# MSPM0L134X register map
Vendor: Texas Instruments; File version: This preliminary header file does not have a version number - build date: 2023-02-21 16:43:37
CPU: CM0 r0p1, little endian, MPU, no FPU, 3 interrupt priority bits
Registers are 32-bit, read-write, reset 0x0 unless marked. A register's access mark holds for its fields unless they carry their own. Offsets are from the block's base; [hi:lo] are bit positions; {n}, {i} and the like mark numbered series.

## SYSCTL — mem_map
Base 0x400AF000
0x1020 IIDX ro — SYSCTL interrupt index
  [1:0] IIDX_STAT — The SYSCTL interrupt index (IIDX) register generates a value corresponding to the highest priority pending interrupt source. This value may be used as an address offset for fast, deterministic handling in the interrupt service routine. A read of the IIDX register will clear the corresponding interrupt status in the RIS and MIS registers.
    0=IIDX_STAT_NO_INTR (NO_INTR); 1=IIDX_STAT_LFOSCGOOD (LFOSCGOOD); 2=IIDX_STAT_ANACLKERR (ANACLKERR)
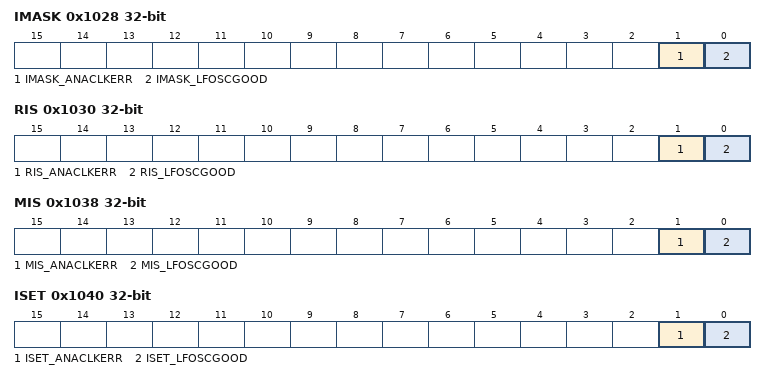
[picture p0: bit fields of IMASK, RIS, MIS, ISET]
0x1028 IMASK — SYSCTL interrupt mask
  [1] IMASK_ANACLKERR — Analog Clocking Consistency Error
    0=IMASK_ANACLKERR_DISABLE (DISABLE); 1=IMASK_ANACLKERR_ENABLE (ENABLE)
  [0] IMASK_LFOSCGOOD — Enable or disable the LFOSCGOOD interrupt. LFOSCGOOD indicates that the LFOSC has started successfully.
    0=IMASK_LFOSCGOOD_DISABLE (DISABLE); 1=IMASK_LFOSCGOOD_ENABLE (ENABLE)
0x1030 RIS ro — SYSCTL raw interrupt status
  [1] RIS_ANACLKERR — Analog Clocking Consistency Error
    0=RIS_ANACLKERR_FALSE (FALSE); 1=RIS_ANACLKERR_TRUE (TRUE)
  [0] RIS_LFOSCGOOD — Raw status of the LFOSCGOOD interrupt.
    0=RIS_LFOSCGOOD_FALSE (FALSE); 1=RIS_LFOSCGOOD_TRUE (TRUE)
0x1038 MIS ro — SYSCTL masked interrupt status
  [1] MIS_ANACLKERR — Analog Clocking Consistency Error
    0=MIS_ANACLKERR_FALSE (FALSE); 1=MIS_ANACLKERR_TRUE (TRUE)
  [0] MIS_LFOSCGOOD — Masked status of the LFOSCGOOD interrupt.
    0=MIS_LFOSCGOOD_FALSE (FALSE); 1=MIS_LFOSCGOOD_TRUE (TRUE)
0x1040 ISET wo — SYSCTL interrupt set
  [1] ISET_ANACLKERR — Analog Clocking Consistency Error
    0=ISET_ANACLKERR_NO_EFFECT (NO_EFFECT); 1=ISET_ANACLKERR_SET (SET)
  [0] ISET_LFOSCGOOD — Set the LFOSCGOOD interrupt.
    0=ISET_LFOSCGOOD_NO_EFFECT (NO_EFFECT); 1=ISET_LFOSCGOOD_SET (SET)
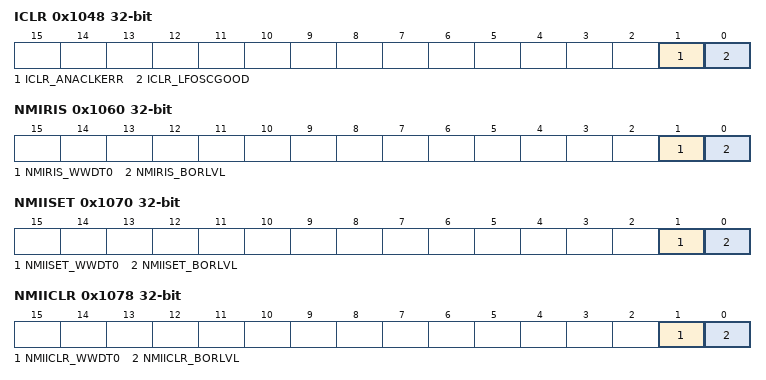
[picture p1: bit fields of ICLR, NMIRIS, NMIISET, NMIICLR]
0x1048 ICLR wo — SYSCTL interrupt clear
  [1] ICLR_ANACLKERR — Analog Clocking Consistency Error
    0=ICLR_ANACLKERR_NO_EFFECT (NO_EFFECT); 1=ICLR_ANACLKERR_CLR (CLR)
  [0] ICLR_LFOSCGOOD — Clear the LFOSCGOOD interrupt.
    0=ICLR_LFOSCGOOD_NO_EFFECT (NO_EFFECT); 1=ICLR_LFOSCGOOD_CLR (CLR)
0x1050 NMIIIDX ro — NMI interrupt index
  [1:0] NMIIIDX_STAT — The NMI interrupt index (NMIIIDX) register generates a value corresponding to the highest priority pending NMI source. This value may be used as an address offset for fast, deterministic handling in the NMI service routine. A read of the NMIIIDX register will clear the corresponding interrupt status in the NMIRIS register.
    0=NMIIIDX_STAT_NO_INTR (NO_INTR); 1=NMIIIDX_STAT_BORLVL (BORLVL); 2=NMIIIDX_STAT_WWDT0 (WWDT0)
0x1060 NMIRIS ro — NMI raw interrupt status
  [1] NMIRIS_WWDT0 — Watch Dog 0 Fault
    0=NMIRIS_WWDT0_FALSE (FALSE); 1=NMIRIS_WWDT0_TRUE (TRUE)
  [0] NMIRIS_BORLVL — Raw status of the BORLVL NMI
    0=NMIRIS_BORLVL_FALSE (FALSE); 1=NMIRIS_BORLVL_TRUE (TRUE)
0x1070 NMIISET wo — NMI interrupt set
  [1] NMIISET_WWDT0 — Watch Dog 0 Fault
    0=NMIISET_WWDT0_NO_EFFECT (NO_EFFECT); 1=NMIISET_WWDT0_SET (SET)
  [0] NMIISET_BORLVL — Set the BORLVL NMI
    0=NMIISET_BORLVL_NO_EFFECT (NO_EFFECT); 1=NMIISET_BORLVL_SET (SET)
0x1078 NMIICLR wo — NMI interrupt clear
  [1] NMIICLR_WWDT0 — Watch Dog 0 Fault
    0=NMIICLR_WWDT0_NO_EFFECT (NO_EFFECT); 1=NMIICLR_WWDT0_CLR (CLR)
  [0] NMIICLR_BORLVL — Clr the BORLVL NMI
    0=NMIICLR_BORLVL_NO_EFFECT (NO_EFFECT); 1=NMIICLR_BORLVL_CLR (CLR)
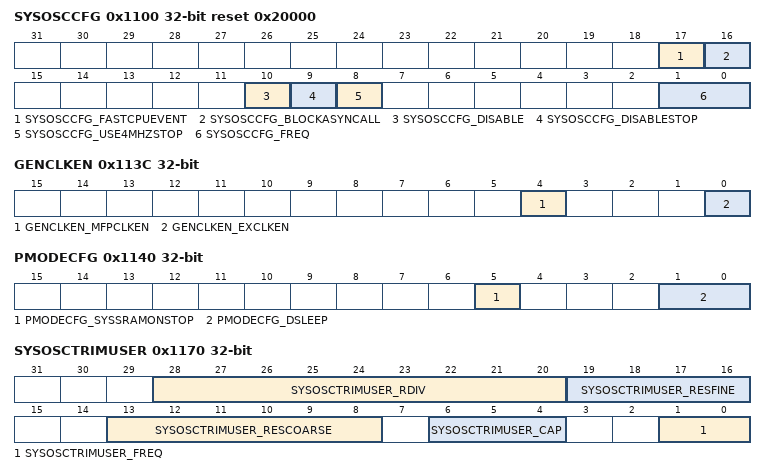
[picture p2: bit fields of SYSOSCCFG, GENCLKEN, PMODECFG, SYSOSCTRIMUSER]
0x1100 SYSOSCCFG reset 0x20000 — SYSOSC configuration
  [17] SYSOSCCFG_FASTCPUEVENT — FASTCPUEVENT may be used to assert a fast clock request when an interrupt is asserted to the CPU, reducing interrupt latency.
    0=SYSOSCCFG_FASTCPUEVENT_DISABLE (DISABLE); 1=SYSOSCCFG_FASTCPUEVENT_ENABLE (ENABLE)
  [16] SYSOSCCFG_BLOCKASYNCALL — BLOCKASYNCALL may be used to mask block all asynchronous fast clock requests, preventing hardware from dynamically changing the active clock configuration when operating in a given mode.
    0=SYSOSCCFG_BLOCKASYNCALL_DISABLE (DISABLE); 1=SYSOSCCFG_BLOCKASYNCALL_ENABLE (ENABLE)
  [10] SYSOSCCFG_DISABLE — DISABLE sets the SYSOSC enable/disable policy. SYSOSC may be powered off in RUN, SLEEP, and STOP modes to reduce power consumption. When SYSOSC is disabled, MCLK and ULPCLK are sourced from LFCLK.
    0=SYSOSCCFG_DISABLE_DISABLE (DISABLE); 1=SYSOSCCFG_DISABLE_ENABLE (ENABLE)
  [9] SYSOSCCFG_DISABLESTOP — DISABLESTOP sets the SYSOSC stop mode enable/disable policy. When operating in STOP mode, the SYSOSC may be automatically disabled. When set, ULPCLK will run from LFCLK in STOP mode and SYSOSC will be disabled to reduce power consumption.
    0=SYSOSCCFG_DISABLESTOP_DISABLE (DISABLE); 1=SYSOSCCFG_DISABLESTOP_ENABLE (ENABLE)
  [8] SYSOSCCFG_USE4MHZSTOP — USE4MHZSTOP sets the SYSOSC stop mode frequency policy. When entering STOP mode, the SYSOSC frequency may be automatically switched to 4MHz to reduce SYSOSC power consumption.
    0=SYSOSCCFG_USE4MHZSTOP_DISABLE (DISABLE); 1=SYSOSCCFG_USE4MHZSTOP_ENABLE (ENABLE)
  [1:0] SYSOSCCFG_FREQ — Target operating frequency for the system oscillator (SYSOSC)
    0=SYSOSCCFG_FREQ_SYSOSCBASE (SYSOSCBASE); 1=SYSOSCCFG_FREQ_SYSOSC4M (SYSOSC4M); 2=SYSOSCCFG_FREQ_SYSOSCUSER (SYSOSCUSER); 3=SYSOSCCFG_FREQ_SYSOSCTURBO (SYSOSCTURBO)
0x113C GENCLKEN — General clock enable control
  [4] GENCLKEN_MFPCLKEN — MFPCLKEN enables the middle frequency precision clock (MFPCLK).
    0=GENCLKEN_MFPCLKEN_DISABLE (DISABLE); 1=GENCLKEN_MFPCLKEN_ENABLE (ENABLE)
  [0] GENCLKEN_EXCLKEN — EXCLKEN enables the CLK_OUT external clock output block.
    0=GENCLKEN_EXCLKEN_DISABLE (DISABLE); 1=GENCLKEN_EXCLKEN_ENABLE (ENABLE)
0x1140 PMODECFG — Power mode configuration
  [5] PMODECFG_SYSSRAMONSTOP — SYSSRAMONSTOP selects whether the SRAM controller is enabled or disabled in STOP mode.
    0=PMODECFG_SYSSRAMONSTOP_DISABLE (DISABLE); 1=PMODECFG_SYSSRAMONSTOP_ENABLE (ENABLE)
  [1:0] PMODECFG_DSLEEP — DSLEEP selects the operating mode to enter upon a DEEPSLEEP request from the CPU.
    0=PMODECFG_DSLEEP_STOP (STOP); 1=PMODECFG_DSLEEP_STANDBY (STANDBY); 2=PMODECFG_DSLEEP_SHUTDOWN (SHUTDOWN)
0x1150 FCC ro — Frequency clock counter (FCC) count
  [21:0] FCC_DATA — Frequency clock counter (FCC) count value.
0x1170 SYSOSCTRIMUSER — SYSOSC user-specified trim
  [28:20] SYSOSCTRIMUSER_RDIV — RDIV specifies the frequency correction loop (FCL) resistor trim. This value changes with the target frequency.
  [19:16] SYSOSCTRIMUSER_RESFINE — RESFINE specifies the resister fine trim. This value changes with the target frequency.
  [13:8] SYSOSCTRIMUSER_RESCOARSE — RESCOARSE specifies the resister coarse trim. This value changes with the target frequency.
  [6:4] SYSOSCTRIMUSER_CAP — CAP specifies the SYSOSC capacitor trim. This value changes with the target frequency.
  [1:0] SYSOSCTRIMUSER_FREQ — FREQ specifies the target user-trimmed frequency for SYSOSC.
    1=SYSOSCTRIMUSER_FREQ_SYSOSC16M (SYSOSC16M); 2=SYSOSCTRIMUSER_FREQ_SYSOSC24M (SYSOSC24M)
0x1178 SRAMBOUNDARY — SRAM Write Boundary
  [19:5] SRAMBOUNDARY_ADDR — SRAM boundary configuration. The value configured into this acts such that: SRAM accesses to addresses less than or equal value will be RW only. SRAM accesses to addresses greater than value will be RX only. Value of 0 is not valid (system will have no stack). If set to 0, the system acts as if the entire SRAM is RWX. Any non-zero value can be configured, including a value = SRAM size.
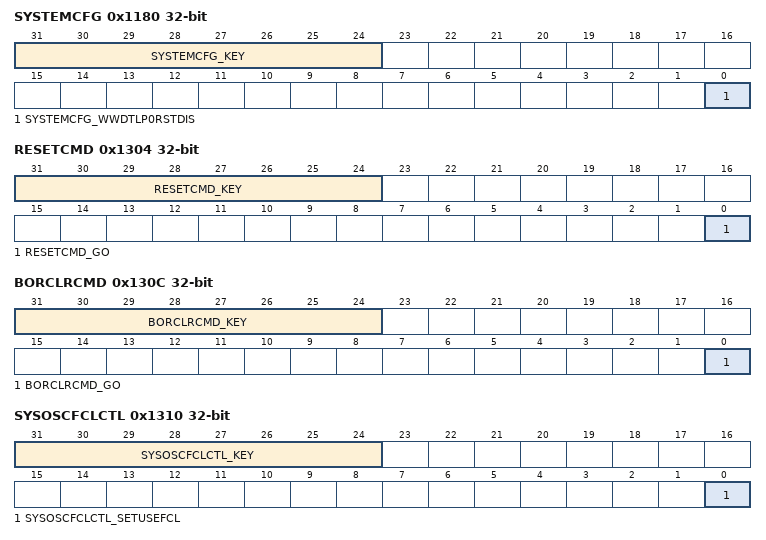
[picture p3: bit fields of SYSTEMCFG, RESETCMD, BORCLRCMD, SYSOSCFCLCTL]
0x1180 SYSTEMCFG — System configuration
  [31:24] SYSTEMCFG_KEY wo — The key value of 1Bh (27) must be written to KEY together with contents to be updated. Reads as 0
    27=SYSTEMCFG_KEY_VALUE (VALUE)
  [0] SYSTEMCFG_WWDTLP0RSTDIS — WWDTLP0RSTDIS specifies whether a WWDT Error Event will trigger a BOOTRST or an NMI.
    0=SYSTEMCFG_WWDTLP0RSTDIS_FALSE (FALSE); 1=SYSTEMCFG_WWDTLP0RSTDIS_TRUE (TRUE)
0x1200 WRITELOCK — SYSCTL register write lockout
  [0] WRITELOCK_ACTIVE — ACTIVE controls whether critical SYSCTL registers are write protected or not.
    0=WRITELOCK_ACTIVE_DISABLE (DISABLE); 1=WRITELOCK_ACTIVE_ENABLE (ENABLE)
0x1220 RSTCAUSE ro — Reset cause
  [4:0] RSTCAUSE_ID — ID is a read-to-clear field which indicates the lowest level reset cause since the last read.
    0=RSTCAUSE_ID_NORST (NORST); 1=RSTCAUSE_ID_PORHWFAIL (PORHWFAIL); 2=RSTCAUSE_ID_POREXNRST (POREXNRST); 3=RSTCAUSE_ID_PORSW (PORSW); 4=RSTCAUSE_ID_BORSUPPLY (BORSUPPLY); 5=RSTCAUSE_ID_BORWAKESHUTDN (BORWAKESHUTDN); 8=RSTCAUSE_ID_BOOTNONPMUPARITY (BOOTNONPMUPARITY); 9=RSTCAUSE_ID_BOOTCLKFAIL (BOOTCLKFAIL); 12=RSTCAUSE_ID_BOOTEXNRST (BOOTEXNRST); 13=RSTCAUSE_ID_BOOTSW (BOOTSW); 14=RSTCAUSE_ID_SYSWWDT0 (SYSWWDT0); 16=RSTCAUSE_ID_SYSBSLEXIT (SYSBSLEXIT); 17=RSTCAUSE_ID_SYSBSLENTRY (SYSBSLENTRY); 19=RSTCAUSE_ID_SYSWWDT1 (SYSWWDT1); 20=RSTCAUSE_ID_SYSFLASHECC (SYSFLASHECC); 21=RSTCAUSE_ID_SYSCPULOCK (SYSCPULOCK); 26=RSTCAUSE_ID_SYSDBG (SYSDBG); 27=RSTCAUSE_ID_SYSSW (SYSSW); 28=RSTCAUSE_ID_CPUDBG (CPUDBG); 29=RSTCAUSE_ID_CPUSW (CPUSW)
0x1300 RESETLEVEL — Reset level for application-triggered reset command
  [2:0] RESETLEVEL_LEVEL — LEVEL is used to specify the type of reset to be issued when RESETCMD is set to generate a software triggered reset.
    0=RESETLEVEL_LEVEL_CPU (CPU); 1=RESETLEVEL_LEVEL_BOOT (BOOT); 2=RESETLEVEL_LEVEL_BOOTLOADERENTRY (BOOTLOADERENTRY); 3=RESETLEVEL_LEVEL_POR (POR); 4=RESETLEVEL_LEVEL_BOOTLOADEREXIT (BOOTLOADEREXIT)
0x1304 RESETCMD wo — Execute an application-triggered reset command
  [31:24] RESETCMD_KEY — The key value of E4h (228) must be written to KEY together with GO to trigger the reset.
    228=RESETCMD_KEY_VALUE (VALUE)
  [0] RESETCMD_GO — Execute the reset specified in RESETLEVEL.LEVEL. Must be written together with the KEY.
    1=RESETCMD_GO_TRUE (TRUE)
0x1308 BORTHRESHOLD — BOR threshold selection
  [1:0] BORTHRESHOLD_LEVEL — LEVEL specifies the desired BOR threshold and BOR mode.
    0=BORTHRESHOLD_LEVEL_BORMIN (BORMIN); 1=BORTHRESHOLD_LEVEL_BORLEVEL1 (BORLEVEL1); 2=BORTHRESHOLD_LEVEL_BORLEVEL2 (BORLEVEL2); 3=BORTHRESHOLD_LEVEL_BORLEVEL3 (BORLEVEL3)
0x130C BORCLRCMD wo — Set the BOR threshold
  [31:24] BORCLRCMD_KEY — The key value of C7h (199) must be written to KEY together with GO to trigger the clear and BOR threshold change.
    199=BORCLRCMD_KEY_VALUE (VALUE)
  [0] BORCLRCMD_GO — GO clears any prior BOR violation status indications and attempts to change the active BOR mode to that specified in the LEVEL field of the BORTHRESHOLD register.
    1=BORCLRCMD_GO_TRUE (TRUE)
0x1310 SYSOSCFCLCTL wo — SYSOSC frequency correction loop (FCL) ROSC enable
  [31:24] SYSOSCFCLCTL_KEY — The key value of 2Ah (42) must be written to KEY together with SETUSEFCL to enable the FCL.
    42=SYSOSCFCLCTL_KEY_VALUE (VALUE)
  [0] SYSOSCFCLCTL_SETUSEFCL — Set SETUSEFCL to enable the frequency correction loop in SYSOSC. Once enabled, this state is locked until the next BOOTRST.
    1=SYSOSCFCLCTL_SETUSEFCL_TRUE (TRUE)
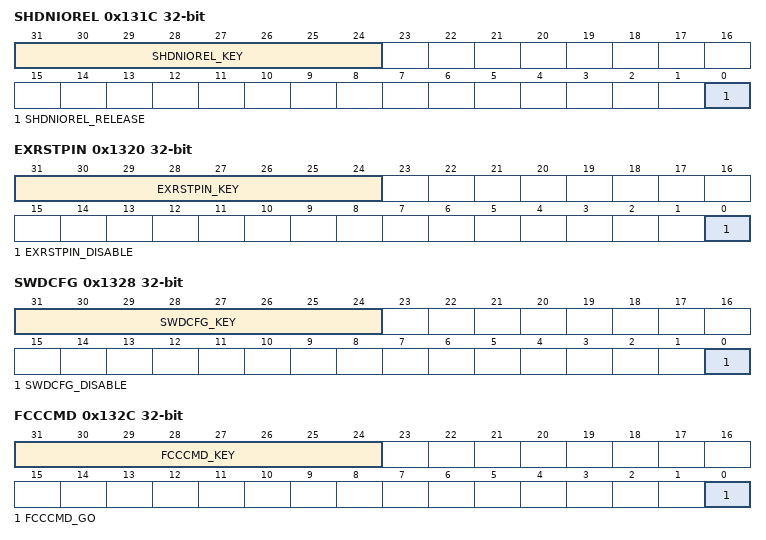
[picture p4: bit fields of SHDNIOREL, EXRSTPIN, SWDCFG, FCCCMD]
0x131C SHDNIOREL wo — SHUTDOWN IO release control
  [31:24] SHDNIOREL_KEY — The key value 91h must be written to KEY together with RELEASE to set RELEASE.
    145=SHDNIOREL_KEY_VALUE (VALUE)
  [0] SHDNIOREL_RELEASE — Set RELEASE to release the IO after a SHUTDOWN mode exit.
    1=SHDNIOREL_RELEASE_TRUE (TRUE)
0x1320 EXRSTPIN wo — Disable the reset function of the NRST pin
  [31:24] EXRSTPIN_KEY — The key value 1Eh must be written together with DISABLE to disable the reset function.
    30=EXRSTPIN_KEY_VALUE (VALUE)
  [0] EXRSTPIN_DISABLE — Set DISABLE to disable the reset function of the NRST pin. Once set, this configuration is locked until the next POR.
    0=EXRSTPIN_DISABLE_FALSE (FALSE); 1=EXRSTPIN_DISABLE_TRUE (TRUE)
0x1328 SWDCFG wo — Disable the SWD function on the SWD pins
  [31:24] SWDCFG_KEY — The key value 62h (98) must be written to KEY together with DISBALE to disable the SWD functions.
    98=SWDCFG_KEY_VALUE (VALUE)
  [0] SWDCFG_DISABLE — Set DISABLE to disable the SWD function on SWD pins, allowing the SWD pins to be used as GPIO.
    1=SWDCFG_DISABLE_TRUE (TRUE)
0x132C FCCCMD wo — Frequency clock counter start capture
  [31:24] FCCCMD_KEY — The key value 0Eh (14) must be written with GO to start a capture.
    14=FCCCMD_KEY_VALUE (VALUE)
  [0] FCCCMD_GO — Set GO to start a capture with the frequency clock counter (FCC).
    1=FCCCMD_GO_TRUE (TRUE)
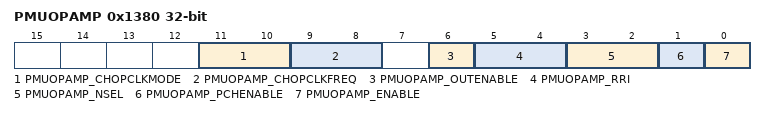
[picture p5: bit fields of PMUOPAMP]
0x1380 PMUOPAMP — GPAMP control
  [11:10] PMUOPAMP_CHOPCLKMODE — CHOPCLKMODE selects the GPAMP chopping mode.
    0=PMUOPAMP_CHOPCLKMODE_CHOPDISABLED (CHOPDISABLED); 1=PMUOPAMP_CHOPCLKMODE_REGCHOP (REGCHOP); 2=PMUOPAMP_CHOPCLKMODE_ADCASSIST (ADCASSIST)
  [9:8] PMUOPAMP_CHOPCLKFREQ — CHOPCLKFREQ selects the GPAMP chopping clock frequency
    0=PMUOPAMP_CHOPCLKFREQ_CLK16KHZ (CLK16KHZ); 1=PMUOPAMP_CHOPCLKFREQ_CLK8KHZ (CLK8KHZ); 2=PMUOPAMP_CHOPCLKFREQ_CLK4KHZ (CLK4KHZ); 3=PMUOPAMP_CHOPCLKFREQ_CLK2KHZ (CLK2KHZ)
  [6] PMUOPAMP_OUTENABLE — Set OUTENABLE to connect the GPAMP output signal to the GPAMP_OUT pin
    0=PMUOPAMP_OUTENABLE_FALSE (FALSE); 1=PMUOPAMP_OUTENABLE_TRUE (TRUE)
  [5:4] PMUOPAMP_RRI — RRI selects the rail-to-rail input mode.
    {v}=PMUOPAMP_RRI_MODE{v} (MODE{v}) (v=0..3)
  [3:2] PMUOPAMP_NSEL — NSEL selects the GPAMP negative channel input.
    {v}=PMUOPAMP_NSEL_SEL{v} (SEL{v}) (v=0..3)
  [1] PMUOPAMP_PCHENABLE — Set PCHENABLE to enable the positive channel input.
    0=PMUOPAMP_PCHENABLE_FALSE (FALSE); 1=PMUOPAMP_PCHENABLE_TRUE (TRUE)
  [0] PMUOPAMP_ENABLE — Set ENABLE to turn on the GPAMP.
    0=PMUOPAMP_ENABLE_FALSE (FALSE); 1=PMUOPAMP_ENABLE_TRUE (TRUE)
{0x1400+4i} SHUTDNSTORE{i} (i=0..3) — Shutdown storage memory (byte {i})
  [7:0] SHUTDNSTORE{i}_DATA — Shutdown storage byte {i}
